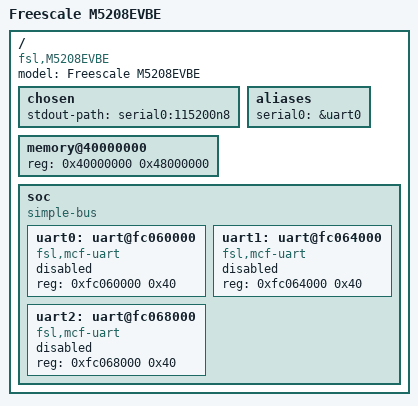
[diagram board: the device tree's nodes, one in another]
/dts-v1/;

/ {
    model = "Freescale M5208EVBE";
    compatible = "fsl,M5208EVBE", "fsl,mcf5208";

    #address-cells = <1>;
    #size-cells = <1>;

    chosen {
        stdout-path = "serial0:115200n8";
    };

    memory@40000000 {
        device_type = "memory";
        reg = <0x40000000 0x48000000>;
    };

    aliases {
        serial0 = &uart0;
    };

    soc {
        compatible = "simple-bus";
        #address-cells = <1>;
        #size-cells = <1>;

        uart0: uart@fc060000 {
            compatible = "fsl,mcf-uart";
            reg = <0xfc060000 0x40>;
            status = "disabled";
        };

        uart1: uart@fc064000 {
            compatible = "fsl,mcf-uart";
            reg = <0xfc064000 0x40>;
            status = "disabled";
        };

        uart2: uart@fc068000 {
            compatible = "fsl,mcf-uart";
            reg = <0xfc068000 0x40>;
            status = "disabled";
        };
    };
};
